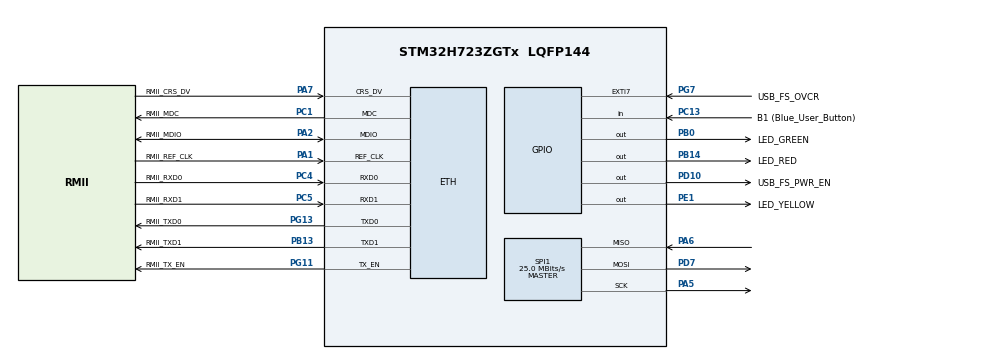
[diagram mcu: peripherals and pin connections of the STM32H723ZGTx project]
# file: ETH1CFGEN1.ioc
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CORTEX_M7.AccessPermission-Cortex_Memory_Protection_Unit_Region0_Settings=MPU_REGION_NO_ACCESS
CORTEX_M7.AccessPermission-Cortex_Memory_Protection_Unit_Region1_Settings=MPU_REGION_FULL_ACCESS
CORTEX_M7.AccessPermission-Cortex_Memory_Protection_Unit_Region2_Settings=MPU_REGION_FULL_ACCESS
CORTEX_M7.AccessPermission_S-Cortex_Memory_Protection_Unit_Region1_Settings_S=MPU_REGION_FULL_ACCESS
CORTEX_M7.AccessPermission_S-Cortex_Memory_Protection_Unit_Region2_Settings_S=MPU_REGION_FULL_ACCESS
CORTEX_M7.BaseAddress-Cortex_Memory_Protection_Unit_Region0_Settings=0x0
CORTEX_M7.BaseAddress-Cortex_Memory_Protection_Unit_Region1_Settings=0x30000000
CORTEX_M7.BaseAddress-Cortex_Memory_Protection_Unit_Region2_Settings=0x30004000
CORTEX_M7.BaseAddress_S-Cortex_Memory_Protection_Unit_Region1_Settings_S=0x30000000
CORTEX_M7.BaseAddress_S-Cortex_Memory_Protection_Unit_Region2_Settings_S=0x30000000
CORTEX_M7.CPU_DCache=Enabled
CORTEX_M7.CPU_ICache=Enabled
CORTEX_M7.DisableExec-Cortex_Memory_Protection_Unit_Region0_Settings=MPU_INSTRUCTION_ACCESS_DISABLE
CORTEX_M7.DisableExec-Cortex_Memory_Protection_Unit_Region1_Settings=MPU_INSTRUCTION_ACCESS_ENABLE
CORTEX_M7.DisableExec_S-Cortex_Memory_Protection_Unit_Region1_Settings_S=MPU_INSTRUCTION_ACCESS_DISABLE
CORTEX_M7.DisableExec_S-Cortex_Memory_Protection_Unit_Region2_Settings_S=MPU_INSTRUCTION_ACCESS_DISABLE
CORTEX_M7.Enable-Cortex_Memory_Protection_Unit_Region0_Settings=MPU_REGION_ENABLE
CORTEX_M7.Enable-Cortex_Memory_Protection_Unit_Region1_Settings=MPU_REGION_ENABLE
CORTEX_M7.Enable-Cortex_Memory_Protection_Unit_Region2_Settings=MPU_REGION_ENABLE
CORTEX_M7.Enable_S-Cortex_Memory_Protection_Unit_Region1_Settings_S=MPU_REGION_ENABLE
CORTEX_M7.Enable_S-Cortex_Memory_Protection_Unit_Region2_Settings_S=MPU_REGION_ENABLE
CORTEX_M7.IsBufferable-Cortex_Memory_Protection_Unit_Region0_Settings=MPU_ACCESS_BUFFERABLE
CORTEX_M7.IsBufferable-Cortex_Memory_Protection_Unit_Region1_Settings=MPU_ACCESS_BUFFERABLE
CORTEX_M7.IsBufferable_S-Cortex_Memory_Protection_Unit_Region2_Settings_S=MPU_ACCESS_BUFFERABLE
CORTEX_M7.IsShareable-Cortex_Memory_Protection_Unit_Region0_Settings=MPU_ACCESS_SHAREABLE
CORTEX_M7.IsShareable-Cortex_Memory_Protection_Unit_Region1_Settings=MPU_ACCESS_NOT_SHAREABLE
CORTEX_M7.IsShareable-Cortex_Memory_Protection_Unit_Region2_Settings=MPU_ACCESS_SHAREABLE
CORTEX_M7.IsShareable_S-Cortex_Memory_Protection_Unit_Region2_Settings_S=MPU_ACCESS_SHAREABLE
CORTEX_M7.MPU_Control=MPU_PRIVILEGED_DEFAULT
CORTEX_M7.Size-Cortex_Memory_Protection_Unit_Region0_Settings=MPU_REGION_SIZE_4GB
CORTEX_M7.Size-Cortex_Memory_Protection_Unit_Region1_Settings=MPU_REGION_SIZE_1KB
CORTEX_M7.Size-Cortex_Memory_Protection_Unit_Region2_Settings=MPU_REGION_SIZE_16KB
CORTEX_M7.Size_S-Cortex_Memory_Protection_Unit_Region1_Settings_S=MPU_REGION_SIZE_1KB
CORTEX_M7.Size_S-Cortex_Memory_Protection_Unit_Region2_Settings_S=MPU_REGION_SIZE_512B
CORTEX_M7.SubRegionDisable-Cortex_Memory_Protection_Unit_Region0_Settings=0x87
CORTEX_M7.TypeExtField-Cortex_Memory_Protection_Unit_Region0_Settings=MPU_TEX_LEVEL0
CORTEX_M7.TypeExtField-Cortex_Memory_Protection_Unit_Region2_Settings=MPU_TEX_LEVEL1
CORTEX_M7.TypeExtField_S-Cortex_Memory_Protection_Unit_Region1_Settings_S=MPU_TEX_LEVEL0
CORTEX_M7.default_mode_Activation=0
ETH.MediaInterface=HAL_ETH_RMII_MODE
FREERTOS.Tasks01=defaultTask,24,512,StartDefaultTask,Default,NULL,Dynamic,NULL,NULL
FREERTOS.configUSE_NEWLIB_REENTRANT=1
LWIP.BSP.number=1
LWIP.IP_ADDRESS=192.168.001.124
LWIP.LWIP_DHCP=0
LWIP.LWIP_RAM_HEAP_POINTER=0x30004000
LWIP.MEM_SIZE=1024*14
LWIP.NETMASK_ADDRESS=255.255.255.000
LWIP.TCP_MSS=1460
LWIP.TCP_SND_BUF=5840
LWIP.TCP_SND_QUEUELEN=16
LWIP.Version=v2.1.2_Cube
LWIP0.BSP.STBoard=false
LWIP0.BSP.api=BSP_COMPONENT_DRIVER
LWIP0.BSP.component=LAN8742
LWIP0.BSP.instance=LAN8742
LWIP0.BSP.name=Driver_PHY
LWIP0.BSP.semaphore=S_LAN8742
LWIP0.BSP.solution=LAN8742
Mcu.Family=STM32H7
Mcu.Name=STM32H723ZGTx
Mcu.Package=LQFP144
NVIC.ETH_IRQn=true\:5\:0\:false\:false\:true\:true\:true\:true\:true
NVIC.PriorityGroup=NVIC_PRIORITYGROUP_4
NVIC.TIM6_DAC_IRQn=true\:15\:0\:false\:false\:true\:false\:false\:true\:true
NVIC.TimeBase=TIM6_DAC_IRQn
NVIC.TimeBaseIP=TIM6
PA1.GPIO_Label=RMII_REF_CLK
PA1.GPIO_Speed=GPIO_SPEED_FREQ_VERY_HIGH
PA1.Mode=RMII
PA1.Signal=ETH_REF_CLK
PA13(JTMS/SWDIO).GPIO_Label=SWDIO
PA13(JTMS/SWDIO).Mode=Trace_Asynchronous_SW
PA13(JTMS/SWDIO).Signal=DEBUG_JTMS-SWDIO
PA14(JTCK/SWCLK).GPIO_Label=SWCLK
PA14(JTCK/SWCLK).Mode=Trace_Asynchronous_SW
PA14(JTCK/SWCLK).Signal=DEBUG_JTCK-SWCLK
PA2.GPIO_Label=RMII_MDIO
PA2.GPIO_Speed=GPIO_SPEED_FREQ_VERY_HIGH
PA2.Mode=RMII
PA2.Signal=ETH_MDIO
PA5.Mode=Full_Duplex_Master
PA5.Signal=SPI1_SCK
PA6.Mode=Full_Duplex_Master
PA6.Signal=SPI1_MISO
PA7.GPIO_Label=RMII_CRS_DV
PA7.GPIO_Speed=GPIO_SPEED_FREQ_VERY_HIGH
PA7.Mode=RMII
PA7.Signal=ETH_CRS_DV
PB0.GPIO_Label=LED_GREEN
PB0.Signal=GPIO_Output
PB13.GPIO_Label=RMII_TXD1
PB13.GPIO_Speed=GPIO_SPEED_FREQ_VERY_HIGH
PB13.Mode=RMII
PB13.Signal=ETH_TXD1
PB14.GPIO_Label=LED_RED
PB14.Signal=GPIO_Output
PB3(JTDO/TRACESWO).GPIO_Label=SWO
PB3(JTDO/TRACESWO).Mode=Trace_Asynchronous_SW
PB3(JTDO/TRACESWO).Signal=DEBUG_JTDO-SWO
PC1.GPIO_Label=RMII_MDC
PC1.Mode=RMII
PC1.Signal=ETH_MDC
PC13.GPIO_Label=B1 (Blue_User_Button)
PC13.Signal=GPIO_Input
PC4.GPIO_Label=RMII_RXD0
PC4.GPIO_Speed=GPIO_SPEED_FREQ_VERY_HIGH
PC4.Mode=RMII
PC4.Signal=ETH_RXD0
PC5.GPIO_Label=RMII_RXD1
PC5.GPIO_Speed=GPIO_SPEED_FREQ_VERY_HIGH
PC5.Mode=RMII
PC5.Signal=ETH_RXD1
PD10.GPIO_Label=USB_FS_PWR_EN
PD10.Signal=GPIO_Output
PD7.Mode=Full_Duplex_Master
PD7.Signal=SPI1_MOSI
PE1.GPIO_Label=LED_YELLOW
PE1.Signal=GPIO_Output
PG11.GPIO_Label=RMII_TX_EN
PG11.GPIO_Speed=GPIO_SPEED_FREQ_VERY_HIGH
PG11.Mode=RMII
PG11.Signal=ETH_TX_EN
PG13.GPIO_Label=RMII_TXD0
PG13.GPIO_Speed=GPIO_SPEED_FREQ_VERY_HIGH
PG13.Mode=RMII
PG13.Signal=ETH_TXD0
PG7.GPIO_Label=USB_FS_OVCR
PG7.Signal=GPXTI7
PH0-OSC_IN.GPIO_Label=MCO
PH0-OSC_IN.Mode=HSE-External-Clock-Source
PH0-OSC_IN.Signal=RCC_OSC_IN
ProjectManager.HeapSize=0x200
ProjectManager.StackSize=0x400
ProjectManager.TargetToolchain=STM32CubeIDE
RCC.ADCFreq_Value=76000000
RCC.APB1Freq_Value=125000000
RCC.APB2Freq_Value=125000000
RCC.APB3Freq_Value=125000000
RCC.APB4Freq_Value=125000000
RCC.CortexFreq_Value=500000000
RCC.D1PPRE=RCC_APB3_DIV2
RCC.D2PPRE1=RCC_APB1_DIV2
RCC.D2PPRE2=RCC_APB2_DIV2
RCC.D3PPRE=RCC_APB4_DIV2
RCC.DIVM1=4
RCC.DIVM2=1
RCC.DIVN1=250
RCC.DIVN2=19
RCC.DIVP1=1
RCC.DIVQ1=5
RCC.HCLKFreq_Value=250000000
RCC.HPRE=RCC_HCLK_DIV2
RCC.HSE_VALUE=8000000
RCC.PLLFRACN=0
RCC.PLLSourceVirtual=RCC_PLLSOURCE_HSE
RCC.SYSCLKFreq_VALUE=500000000
RCC.SYSCLKSource=RCC_SYSCLKSOURCE_PLLCLK
RCC.USBCLockSelection=RCC_USBCLKSOURCE_HSI48
RCC.USBFreq_Value=48000000
SPI1.BaudRatePrescaler=SPI_BAUDRATEPRESCALER_4
SPI1.CalculateBaudRate=25.0 MBits/s
SPI1.DataSize=SPI_DATASIZE_32BIT
SPI1.Direction=SPI_DIRECTION_2LINES
SPI1.Mode=SPI_MODE_MASTER
SPI1.VirtualType=VM_MASTER
VP_FREERTOS_VS_CMSIS_V2.Mode=CMSIS_V2
VP_LWIP_VS_Enabled.Mode=Enabled
VP_SYS_VS_tim6.Mode=TIM6
board=NUCLEO-H723ZG

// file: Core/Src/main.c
/* USER CODE BEGIN Header */
/**
  ******************************************************************************
  * @file           : main.c
  * @brief          : Main program body
  ******************************************************************************
  * @attention
  *
  * Copyright (c) 2023 STMicroelectronics.
  * All rights reserved.
  *
  * This software is licensed under terms that can be found in the LICENSE file
  * in the root directory of this software component.
  * If no LICENSE file comes with this software, it is provided AS-IS.
  *
  ******************************************************************************
  */
/* USER CODE END Header */
#include "main.h"
#include "cmsis_os.h"
#include "lwip.h"

SPI_HandleTypeDef hspi1;

/* Definitions for defaultTask */
osThreadId_t defaultTaskHandle;
const osThreadAttr_t defaultTask_attributes = {
  .name = "defaultTask",
  .stack_size = 512 * 4,
  .priority = (osPriority_t) osPriorityNormal,
};

void SystemClock_Config(void);
static void MPU_Config(void);
static void MX_GPIO_Init(void);
static void MX_SPI1_Init(void);
void StartDefaultTask(void *argument);

int main(void)
{

  /* MPU Configuration--------------------------------------------------------*/
  MPU_Config();

  /* Enable I-Cache---------------------------------------------------------*/
  SCB_EnableICache();

  /* Enable D-Cache---------------------------------------------------------*/
  SCB_EnableDCache();

  /* MCU Configuration--------------------------------------------------------*/

  /* Reset of all peripherals, Initializes the Flash interface and the Systick. */
  HAL_Init();

  /* Configure the system clock */
  SystemClock_Config();

  /* Initialize all configured peripherals */
  MX_GPIO_Init();
  MX_SPI1_Init();

  /* Init scheduler */
  osKernelInitialize();

  /* Create the thread(s) */
  /* creation of defaultTask */
  defaultTaskHandle = osThreadNew(StartDefaultTask, NULL, &defaultTask_attributes);

  /* Start scheduler */
  osKernelStart();
  /* We should never get here as control is now taken by the scheduler */
  /* Infinite loop */
  while (1)
  {

  }
}

void SystemClock_Config(void)
{
  RCC_OscInitTypeDef RCC_OscInitStruct = {0};
  RCC_ClkInitTypeDef RCC_ClkInitStruct = {0};

  /** Supply configuration update enable
  */
  HAL_PWREx_ConfigSupply(PWR_LDO_SUPPLY);

  /** Configure the main internal regulator output voltage
  */
  __HAL_PWR_VOLTAGESCALING_CONFIG(PWR_REGULATOR_VOLTAGE_SCALE0);

  while(!__HAL_PWR_GET_FLAG(PWR_FLAG_VOSRDY)) {}

  /** Initializes the RCC Oscillators according to the specified parameters
  * in the RCC_OscInitTypeDef structure.
  */
  RCC_OscInitStruct.OscillatorType = RCC_OSCILLATORTYPE_HSE;
  RCC_OscInitStruct.HSEState = RCC_HSE_BYPASS;
  RCC_OscInitStruct.PLL.PLLState = RCC_PLL_ON;
  RCC_OscInitStruct.PLL.PLLSource = RCC_PLLSOURCE_HSE;
  RCC_OscInitStruct.PLL.PLLM = 4;
  RCC_OscInitStruct.PLL.PLLN = 250;
  RCC_OscInitStruct.PLL.PLLP = 1;
  RCC_OscInitStruct.PLL.PLLQ = 5;
  RCC_OscInitStruct.PLL.PLLR = 2;
  RCC_OscInitStruct.PLL.PLLRGE = RCC_PLL1VCIRANGE_1;
  RCC_OscInitStruct.PLL.PLLVCOSEL = RCC_PLL1VCOWIDE;
  RCC_OscInitStruct.PLL.PLLFRACN = 0;
  if (HAL_RCC_OscConfig(&RCC_OscInitStruct) != HAL_OK)
  {
    Error_Handler();
  }

  /** Initializes the CPU, AHB and APB buses clocks
  */
  RCC_ClkInitStruct.ClockType = RCC_CLOCKTYPE_HCLK|RCC_CLOCKTYPE_SYSCLK
                              |RCC_CLOCKTYPE_PCLK1|RCC_CLOCKTYPE_PCLK2
                              |RCC_CLOCKTYPE_D3PCLK1|RCC_CLOCKTYPE_D1PCLK1;
  RCC_ClkInitStruct.SYSCLKSource = RCC_SYSCLKSOURCE_PLLCLK;
  RCC_ClkInitStruct.SYSCLKDivider = RCC_SYSCLK_DIV1;
  RCC_ClkInitStruct.AHBCLKDivider = RCC_HCLK_DIV2;
  RCC_ClkInitStruct.APB3CLKDivider = RCC_APB3_DIV2;
  RCC_ClkInitStruct.APB1CLKDivider = RCC_APB1_DIV2;
  RCC_ClkInitStruct.APB2CLKDivider = RCC_APB2_DIV2;
  RCC_ClkInitStruct.APB4CLKDivider = RCC_APB4_DIV2;

  if (HAL_RCC_ClockConfig(&RCC_ClkInitStruct, FLASH_LATENCY_3) != HAL_OK)
  {
    Error_Handler();
  }
}

static void MX_SPI1_Init(void)
{

  /* SPI1 parameter configuration*/
  hspi1.Instance = SPI1;
  hspi1.Init.Mode = SPI_MODE_MASTER;
  hspi1.Init.Direction = SPI_DIRECTION_2LINES;
  hspi1.Init.DataSize = SPI_DATASIZE_32BIT;
  hspi1.Init.CLKPolarity = SPI_POLARITY_LOW;
  hspi1.Init.CLKPhase = SPI_PHASE_1EDGE;
  hspi1.Init.NSS = SPI_NSS_SOFT;
  hspi1.Init.BaudRatePrescaler = SPI_BAUDRATEPRESCALER_4;
  hspi1.Init.FirstBit = SPI_FIRSTBIT_MSB;
  hspi1.Init.TIMode = SPI_TIMODE_DISABLE;
  hspi1.Init.CRCCalculation = SPI_CRCCALCULATION_DISABLE;
  hspi1.Init.CRCPolynomial = 0x0;
  hspi1.Init.NSSPMode = SPI_NSS_PULSE_ENABLE;
  hspi1.Init.NSSPolarity = SPI_NSS_POLARITY_LOW;
  hspi1.Init.FifoThreshold = SPI_FIFO_THRESHOLD_01DATA;
  hspi1.Init.TxCRCInitializationPattern = SPI_CRC_INITIALIZATION_ALL_ZERO_PATTERN;
  hspi1.Init.RxCRCInitializationPattern = SPI_CRC_INITIALIZATION_ALL_ZERO_PATTERN;
  hspi1.Init.MasterSSIdleness = SPI_MASTER_SS_IDLENESS_00CYCLE;
  hspi1.Init.MasterInterDataIdleness = SPI_MASTER_INTERDATA_IDLENESS_00CYCLE;
  hspi1.Init.MasterReceiverAutoSusp = SPI_MASTER_RX_AUTOSUSP_DISABLE;
  hspi1.Init.MasterKeepIOState = SPI_MASTER_KEEP_IO_STATE_DISABLE;
  hspi1.Init.IOSwap = SPI_IO_SWAP_DISABLE;
  if (HAL_SPI_Init(&hspi1) != HAL_OK)
  {
    Error_Handler();
  }

}

static void MX_GPIO_Init(void)
{
  GPIO_InitTypeDef GPIO_InitStruct = {0};

  /* GPIO Ports Clock Enable */
  __HAL_RCC_GPIOC_CLK_ENABLE();
  __HAL_RCC_GPIOH_CLK_ENABLE();
  __HAL_RCC_GPIOA_CLK_ENABLE();
  __HAL_RCC_GPIOB_CLK_ENABLE();
  __HAL_RCC_GPIOD_CLK_ENABLE();
  __HAL_RCC_GPIOG_CLK_ENABLE();
  __HAL_RCC_GPIOE_CLK_ENABLE();

  /*Configure GPIO pin Output Level */
  HAL_GPIO_WritePin(GPIOB, LED_GREEN_Pin|LED_RED_Pin, GPIO_PIN_RESET);

  /*Configure GPIO pin Output Level */
  HAL_GPIO_WritePin(USB_FS_PWR_EN_GPIO_Port, USB_FS_PWR_EN_Pin, GPIO_PIN_RESET);

  /*Configure GPIO pin Output Level */
  HAL_GPIO_WritePin(LED_YELLOW_GPIO_Port, LED_YELLOW_Pin, GPIO_PIN_RESET);

  /*Configure GPIO pin : B1_Pin */
  GPIO_InitStruct.Pin = B1_Pin;
  GPIO_InitStruct.Mode = GPIO_MODE_INPUT;
  GPIO_InitStruct.Pull = GPIO_NOPULL;
  HAL_GPIO_Init(B1_GPIO_Port, &GPIO_InitStruct);

  /*Configure GPIO pins : LED_GREEN_Pin LED_RED_Pin */
  GPIO_InitStruct.Pin = LED_GREEN_Pin|LED_RED_Pin;
  GPIO_InitStruct.Mode = GPIO_MODE_OUTPUT_PP;
  GPIO_InitStruct.Pull = GPIO_NOPULL;
  GPIO_InitStruct.Speed = GPIO_SPEED_FREQ_LOW;
  HAL_GPIO_Init(GPIOB, &GPIO_InitStruct);

  /*Configure GPIO pin : USB_FS_PWR_EN_Pin */
  GPIO_InitStruct.Pin = USB_FS_PWR_EN_Pin;
  GPIO_InitStruct.Mode = GPIO_MODE_OUTPUT_PP;
  GPIO_InitStruct.Pull = GPIO_NOPULL;
  GPIO_InitStruct.Speed = GPIO_SPEED_FREQ_LOW;
  HAL_GPIO_Init(USB_FS_PWR_EN_GPIO_Port, &GPIO_InitStruct);

  /*Configure GPIO pin : USB_FS_OVCR_Pin */
  GPIO_InitStruct.Pin = USB_FS_OVCR_Pin;
  GPIO_InitStruct.Mode = GPIO_MODE_IT_RISING;
  GPIO_InitStruct.Pull = GPIO_NOPULL;
  HAL_GPIO_Init(USB_FS_OVCR_GPIO_Port, &GPIO_InitStruct);

  /*Configure GPIO pin : LED_YELLOW_Pin */
  GPIO_InitStruct.Pin = LED_YELLOW_Pin;
  GPIO_InitStruct.Mode = GPIO_MODE_OUTPUT_PP;
  GPIO_InitStruct.Pull = GPIO_NOPULL;
  GPIO_InitStruct.Speed = GPIO_SPEED_FREQ_LOW;
  HAL_GPIO_Init(LED_YELLOW_GPIO_Port, &GPIO_InitStruct);

}

void StartDefaultTask(void *argument)
{
  /* init code for LWIP */
  MX_LWIP_Init();
  /* USER CODE BEGIN 5 */
  osDelay(pdMS_TO_TICKS(100));
  SCPI_ServerInit();
  /* Infinite loop */
  for(;;)
  {
    osDelay(1);
  }
  /* USER CODE END 5 */
}

/* MPU Configuration */

void MPU_Config(void)
{
  MPU_Region_InitTypeDef MPU_InitStruct = {0};

  /* Disables the MPU */
  HAL_MPU_Disable();

  /** Initializes and configures the Region and the memory to be protected
  */
  MPU_InitStruct.Enable = MPU_REGION_ENABLE;
  MPU_InitStruct.Number = MPU_REGION_NUMBER0;
  MPU_InitStruct.BaseAddress = 0x0;
  MPU_InitStruct.Size = MPU_REGION_SIZE_4GB;
  MPU_InitStruct.SubRegionDisable = 0x87;
  MPU_InitStruct.TypeExtField = MPU_TEX_LEVEL0;
  MPU_InitStruct.AccessPermission = MPU_REGION_NO_ACCESS;
  MPU_InitStruct.DisableExec = MPU_INSTRUCTION_ACCESS_DISABLE;
  MPU_InitStruct.IsShareable = MPU_ACCESS_SHAREABLE;
  MPU_InitStruct.IsCacheable = MPU_ACCESS_NOT_CACHEABLE;
  MPU_InitStruct.IsBufferable = MPU_ACCESS_BUFFERABLE;

  HAL_MPU_ConfigRegion(&MPU_InitStruct);

  /** Initializes and configures the Region and the memory to be protected
  */
  MPU_InitStruct.Number = MPU_REGION_NUMBER1;
  MPU_InitStruct.BaseAddress = 0x30000000;
  MPU_InitStruct.Size = MPU_REGION_SIZE_1KB;
  MPU_InitStruct.SubRegionDisable = 0x0;
  MPU_InitStruct.AccessPermission = MPU_REGION_FULL_ACCESS;
  MPU_InitStruct.DisableExec = MPU_INSTRUCTION_ACCESS_ENABLE;
  MPU_InitStruct.IsShareable = MPU_ACCESS_NOT_SHAREABLE;

  HAL_MPU_ConfigRegion(&MPU_InitStruct);

  /** Initializes and configures the Region and the memory to be protected
  */
  MPU_InitStruct.Number = MPU_REGION_NUMBER2;
  MPU_InitStruct.BaseAddress = 0x30004000;
  MPU_InitStruct.Size = MPU_REGION_SIZE_16KB;
  MPU_InitStruct.TypeExtField = MPU_TEX_LEVEL1;
  MPU_InitStruct.IsShareable = MPU_ACCESS_SHAREABLE;
  MPU_InitStruct.IsBufferable = MPU_ACCESS_NOT_BUFFERABLE;

  HAL_MPU_ConfigRegion(&MPU_InitStruct);
  /* Enables the MPU */
  HAL_MPU_Enable(MPU_PRIVILEGED_DEFAULT);

}

void HAL_TIM_PeriodElapsedCallback(TIM_HandleTypeDef *htim)
{
  if (htim->Instance == TIM6) {
    HAL_IncTick();
  }
}

void Error_Handler(void)
{
  __disable_irq();
  while (1)
  {
  }
}
